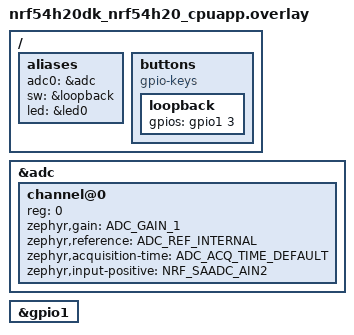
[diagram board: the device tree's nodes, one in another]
/*
 * Copyright (c) 2025 Nordic Semiconductor ASA
 *
 * SPDX-License-Identifier: LicenseRef-Nordic-5-Clause
 */

/* Required GPIO loopback: P1.02 - P1.03 */
/ {
	aliases {
		adc0 = &adc;
		sw = &loopback;
		led = &led0;
		/delete-property/ led1;
	};

	buttons {
		compatible = "gpio-keys";

		loopback: loopback {
			gpios = <&gpio1 3 GPIO_ACTIVE_HIGH>;
		};
	};
};

/delete-node/ &led1;

&adc {
	#address-cells = <1>;
	#size-cells = <0>;

	channel@0 {
		reg = <0>;
		zephyr,gain = "ADC_GAIN_1";
		zephyr,reference = "ADC_REF_INTERNAL";
		zephyr,acquisition-time = <ADC_ACQ_TIME_DEFAULT>;
		zephyr,input-positive = <NRF_SAADC_AIN2>;
	};
};

&gpio1 {
	status = "okay";
};
